VERSION ""

NS_ :

BS_:

BU_: Battery VCU Option1

BO_ 49 Option1_Commands: 1 VCU
 SG_ LED_Signal : 1|3@1+ (1,0) [0|7] ""  Option1
 SG_ LED_Flashing : 0|1@1+ (1,0) [0|1] ""  Option1

BO_ 48 VCU_Commands: 1 Option1
 SG_ SOC_Request : 1|1@1+ (1,0) [0|1] ""  VCU
 SG_ RemoteDrive_Request : 0|1@1+ (1,0) [0|1] "" Vector__XXX

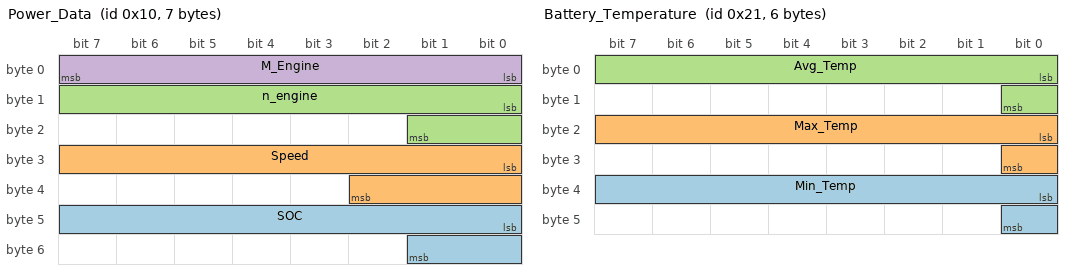
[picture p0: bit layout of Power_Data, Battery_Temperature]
BO_ 16 Power_Data: 7 VCU
 SG_ SOC : 40|10@1+ (0.1,0) [0|102.3] "%" Vector__XXX
 SG_ Speed : 24|11@1+ (0.1,0) [0|204.7] "km/h"  Option1
 SG_ n_engine : 8|10@1+ (1,0) [0|1023] "1/min"  Option1
 SG_ M_Engine : 0|8@1+ (0.1,0) [0|25.5] "Nm"  Option1

BO_ 33 Battery_Temperature: 6 Battery
 SG_ Min_Temp : 32|9@1+ (0.1,0) [0|51.1] "°C"  VCU,Option1
 SG_ Max_Temp : 16|9@1+ (0.1,0) [0|51.1] "°C"  Option1,VCU
 SG_ Avg_Temp : 0|9@1+ (0.1,0) [0|51.1] "°C"  VCU,Option1

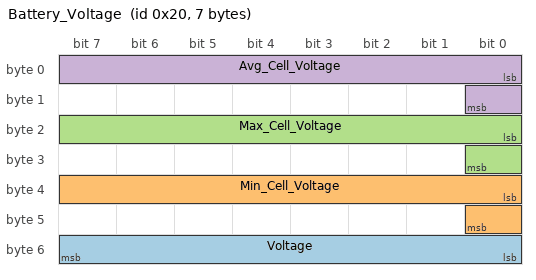
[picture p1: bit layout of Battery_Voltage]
BO_ 32 Battery_Voltage: 7 Battery
 SG_ Voltage : 48|8@1+ (0.1,40) [40|65.5] "V"  Option1,VCU
 SG_ Min_Cell_Voltage : 32|9@1+ (0.01,0) [0|5.11] "V"  VCU,Option1
 SG_ Max_Cell_Voltage : 16|9@1+ (0.01,0) [0|5.11] "V"  VCU,Option1
 SG_ Avg_Cell_Voltage : 0|9@1+ (0.01,0) [0|2.55] "V"  VCU,Option1

BA_DEF_  "BusType" STRING ;
BA_DEF_DEF_  "BusType" "CAN";
